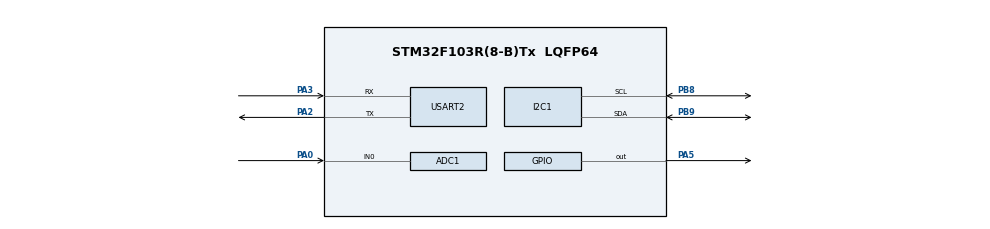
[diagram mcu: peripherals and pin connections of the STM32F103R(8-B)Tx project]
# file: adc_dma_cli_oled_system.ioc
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ADC1.Channel-0\#ChannelRegularConversion=ADC_CHANNEL_0
ADC1.ContinuousConvMode=ENABLE
ADC1.NbrOfConversion=1
ADC1.NbrOfConversionFlag=1
ADC1.Rank-0\#ChannelRegularConversion=1
ADC1.SamplingTime-0\#ChannelRegularConversion=ADC_SAMPLETIME_55CYCLES_5
ADC1.master=1
Dma.Request0=USART2_RX
Dma.USART2_RX.0.Direction=DMA_PERIPH_TO_MEMORY
Dma.USART2_RX.0.Instance=DMA1_Channel6
Dma.USART2_RX.0.MemDataAlignment=DMA_MDATAALIGN_BYTE
Dma.USART2_RX.0.MemInc=DMA_MINC_ENABLE
Dma.USART2_RX.0.Mode=DMA_CIRCULAR
Dma.USART2_RX.0.PeriphDataAlignment=DMA_PDATAALIGN_BYTE
Dma.USART2_RX.0.PeriphInc=DMA_PINC_DISABLE
Dma.USART2_RX.0.Priority=DMA_PRIORITY_LOW
Mcu.Family=STM32F1
Mcu.Name=STM32F103R(8-B)Tx
Mcu.Package=LQFP64
NVIC.DMA1_Channel6_IRQn=true\:0\:0\:false\:false\:true\:false\:true\:true
NVIC.PriorityGroup=NVIC_PRIORITYGROUP_4
NVIC.USART2_IRQn=true\:0\:0\:false\:false\:true\:true\:true\:true
PA0-WKUP.Signal=ADCx_IN0
PA13.Mode=Serial_Wire
PA13.Signal=SYS_JTMS-SWDIO
PA14.Mode=Serial_Wire
PA14.Signal=SYS_JTCK-SWCLK
PA2.Mode=Asynchronous
PA2.Signal=USART2_TX
PA3.Mode=Asynchronous
PA3.Signal=USART2_RX
PA5.Signal=GPIO_Output
PB8.Mode=I2C
PB8.Signal=I2C1_SCL
PB9.Mode=I2C
PB9.Signal=I2C1_SDA
ProjectManager.HeapSize=0x200
ProjectManager.StackSize=0x400
ProjectManager.TargetToolchain=STM32CubeIDE
RCC.APB1Freq_Value=8000000
RCC.APB2Freq_Value=8000000
SH.ADCx_IN0.0=ADC1_IN0,IN0
USART2.VirtualMode=VM_ASYNC
board=custom

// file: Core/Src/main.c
/* USER CODE BEGIN Header */
/**
  ******************************************************************************
  * @file           : main.c
  * @brief          : Main program body
  ******************************************************************************
  * @attention
  *
  * Copyright (c) 2026 STMicroelectronics.
  * All rights reserved.
  *
  * This software is licensed under terms that can be found in the LICENSE file
  * in the root directory of this software component.
  * If no LICENSE file comes with this software, it is provided AS-IS.
  *
  ******************************************************************************
  */
/* USER CODE END Header */
#include "main.h"

/* USER CODE BEGIN Includes */
#include "ssd1306.h"
#include "adc_app.h"
#include "cli.h"
#include <stdio.h>
/* USER CODE END Includes */

ADC_HandleTypeDef hadc1;

I2C_HandleTypeDef hi2c1;

UART_HandleTypeDef huart2;
DMA_HandleTypeDef hdma_usart2_rx;

/* USER CODE BEGIN PV */
#define RX_BUF_SIZE 128
uint8_t dma_rx_buf[RX_BUF_SIZE];
uint16_t old_pos = 0;
/* USER CODE END PV */

void SystemClock_Config(void);
static void MX_GPIO_Init(void);
static void MX_DMA_Init(void);
static void MX_USART2_UART_Init(void);
static void MX_ADC1_Init(void);
static void MX_I2C1_Init(void);

int main(void)
{

  /* MCU Configuration--------------------------------------------------------*/

  /* Reset of all peripherals, Initializes the Flash interface and the Systick. */
  HAL_Init();

  /* Configure the system clock */
  SystemClock_Config();

  /* Initialize all configured peripherals */
  MX_GPIO_Init();
  MX_DMA_Init();
  MX_USART2_UART_Init();
  MX_ADC1_Init();
  MX_I2C1_Init();
  /* USER CODE BEGIN 2 */
  /* Place application initialization code here. */
  SSD1306_Init();
  ADC_App_Init(&hadc1);

  CLI_Init(&huart2);

  HAL_UART_Receive_DMA(&huart2, dma_rx_buf, RX_BUF_SIZE);
  /* USER CODE END 2 */

  /* Infinite loop */
  while (1)
  {
	  uint16_t new_pos = RX_BUF_SIZE - __HAL_DMA_GET_COUNTER(huart2.hdmarx);

	  if (new_pos != old_pos)
	  {
	      if (new_pos > old_pos)
	      {
	          for (uint16_t i = old_pos; i < new_pos; i++)
	              CLI_InputChar(dma_rx_buf[i]);
	      }
	      else
	      {
	          for (uint16_t i = old_pos; i < RX_BUF_SIZE; i++)
	              CLI_InputChar(dma_rx_buf[i]);

	          for (uint16_t i = 0; i < new_pos; i++)
	              CLI_InputChar(dma_rx_buf[i]);
	      }

	      old_pos = new_pos;
	  }

	  SSD1306_SetCursor(0, 32);
	  SSD1306_WriteString("MODE:STOP");

      uint32_t raw = ADC_ReadRaw();
      uint32_t mv = raw * 3300 / 4095;

      char line1[20];
      char line2[20];
      char line3[20];

      sprintf(line1, "ADC:%lu", raw);
      sprintf(line2, "V:%lumV", mv);

      if (system_mode == MODE_STREAM || read_once)
      {
          uint32_t raw = ADC_ReadRaw();
          uint32_t mv = raw * 3300 / 4095;

          char line1[20];
          char line2[20];

          sprintf(line1, "ADC:%lu", raw);
          sprintf(line2, "V:%lumV", mv);

          SSD1306_Clear();

          SSD1306_SetCursor(0, 0);
          SSD1306_WriteString(line1);

          SSD1306_SetCursor(0, 16);
          SSD1306_WriteString(line2);

          SSD1306_SetCursor(0, 32);

          if (HAL_GetTick() < read_flash_until)
          {
              SSD1306_WriteString("READ      ");
          }
          else if (system_mode == MODE_STREAM)
          {
              SSD1306_WriteString("MODE:STREAM");
          }
          else
          {
              SSD1306_WriteString("MODE:STOP  ");
          }

          SSD1306_UpdateScreen();

          read_once = 0;

          HAL_Delay(200);
      }
    /* USER CODE BEGIN 3 */
    /* Place application loop code here. */
  /* USER CODE END 3 */
  }
}

void SystemClock_Config(void)
{
  RCC_OscInitTypeDef RCC_OscInitStruct = {0};
  RCC_ClkInitTypeDef RCC_ClkInitStruct = {0};
  RCC_PeriphCLKInitTypeDef PeriphClkInit = {0};

  /** Initializes the RCC Oscillators according to the specified parameters
  * in the RCC_OscInitTypeDef structure.
  */
  RCC_OscInitStruct.OscillatorType = RCC_OSCILLATORTYPE_HSI;
  RCC_OscInitStruct.HSIState = RCC_HSI_ON;
  RCC_OscInitStruct.HSICalibrationValue = RCC_HSICALIBRATION_DEFAULT;
  RCC_OscInitStruct.PLL.PLLState = RCC_PLL_NONE;
  if (HAL_RCC_OscConfig(&RCC_OscInitStruct) != HAL_OK)
  {
    Error_Handler();
  }

  /** Initializes the CPU, AHB and APB buses clocks
  */
  RCC_ClkInitStruct.ClockType = RCC_CLOCKTYPE_HCLK|RCC_CLOCKTYPE_SYSCLK
                              |RCC_CLOCKTYPE_PCLK1|RCC_CLOCKTYPE_PCLK2;
  RCC_ClkInitStruct.SYSCLKSource = RCC_SYSCLKSOURCE_HSI;
  RCC_ClkInitStruct.AHBCLKDivider = RCC_SYSCLK_DIV1;
  RCC_ClkInitStruct.APB1CLKDivider = RCC_HCLK_DIV1;
  RCC_ClkInitStruct.APB2CLKDivider = RCC_HCLK_DIV1;

  if (HAL_RCC_ClockConfig(&RCC_ClkInitStruct, FLASH_LATENCY_0) != HAL_OK)
  {
    Error_Handler();
  }
  PeriphClkInit.PeriphClockSelection = RCC_PERIPHCLK_ADC;
  PeriphClkInit.AdcClockSelection = RCC_ADCPCLK2_DIV2;
  if (HAL_RCCEx_PeriphCLKConfig(&PeriphClkInit) != HAL_OK)
  {
    Error_Handler();
  }
}

static void MX_ADC1_Init(void)
{

  ADC_ChannelConfTypeDef sConfig = {0};

  /** Common config
  */
  hadc1.Instance = ADC1;
  hadc1.Init.ScanConvMode = ADC_SCAN_DISABLE;
  hadc1.Init.ContinuousConvMode = ENABLE;
  hadc1.Init.DiscontinuousConvMode = DISABLE;
  hadc1.Init.ExternalTrigConv = ADC_SOFTWARE_START;
  hadc1.Init.DataAlign = ADC_DATAALIGN_RIGHT;
  hadc1.Init.NbrOfConversion = 1;
  if (HAL_ADC_Init(&hadc1) != HAL_OK)
  {
    Error_Handler();
  }

  /** Configure Regular Channel
  */
  sConfig.Channel = ADC_CHANNEL_0;
  sConfig.Rank = ADC_REGULAR_RANK_1;
  sConfig.SamplingTime = ADC_SAMPLETIME_55CYCLES_5;
  if (HAL_ADC_ConfigChannel(&hadc1, &sConfig) != HAL_OK)
  {
    Error_Handler();
  }

}

static void MX_I2C1_Init(void)
{

  hi2c1.Instance = I2C1;
  hi2c1.Init.ClockSpeed = 100000;
  hi2c1.Init.DutyCycle = I2C_DUTYCYCLE_2;
  hi2c1.Init.OwnAddress1 = 0;
  hi2c1.Init.AddressingMode = I2C_ADDRESSINGMODE_7BIT;
  hi2c1.Init.DualAddressMode = I2C_DUALADDRESS_DISABLE;
  hi2c1.Init.OwnAddress2 = 0;
  hi2c1.Init.GeneralCallMode = I2C_GENERALCALL_DISABLE;
  hi2c1.Init.NoStretchMode = I2C_NOSTRETCH_DISABLE;
  if (HAL_I2C_Init(&hi2c1) != HAL_OK)
  {
    Error_Handler();
  }

}

static void MX_USART2_UART_Init(void)
{

  huart2.Instance = USART2;
  huart2.Init.BaudRate = 115200;
  huart2.Init.WordLength = UART_WORDLENGTH_8B;
  huart2.Init.StopBits = UART_STOPBITS_1;
  huart2.Init.Parity = UART_PARITY_NONE;
  huart2.Init.Mode = UART_MODE_TX_RX;
  huart2.Init.HwFlowCtl = UART_HWCONTROL_NONE;
  huart2.Init.OverSampling = UART_OVERSAMPLING_16;
  if (HAL_UART_Init(&huart2) != HAL_OK)
  {
    Error_Handler();
  }

}

static void MX_DMA_Init(void)
{

  /* DMA controller clock enable */
  __HAL_RCC_DMA1_CLK_ENABLE();

  /* DMA interrupt init */
  /* DMA1_Channel6_IRQn interrupt configuration */
  HAL_NVIC_SetPriority(DMA1_Channel6_IRQn, 0, 0);
  HAL_NVIC_EnableIRQ(DMA1_Channel6_IRQn);

}

static void MX_GPIO_Init(void)
{
  GPIO_InitTypeDef GPIO_InitStruct = {0};

  /* GPIO Ports Clock Enable */
  __HAL_RCC_GPIOA_CLK_ENABLE();
  __HAL_RCC_GPIOB_CLK_ENABLE();

  /*Configure GPIO pin Output Level */
  HAL_GPIO_WritePin(GPIOA, GPIO_PIN_5, GPIO_PIN_RESET);

  /*Configure GPIO pin : PA5 */
  GPIO_InitStruct.Pin = GPIO_PIN_5;
  GPIO_InitStruct.Mode = GPIO_MODE_OUTPUT_PP;
  GPIO_InitStruct.Pull = GPIO_NOPULL;
  GPIO_InitStruct.Speed = GPIO_SPEED_FREQ_LOW;
  HAL_GPIO_Init(GPIOA, &GPIO_InitStruct);

}

void Error_Handler(void)
{
  __disable_irq();
  while (1)
  {
  }
}
